VERSION ""

NS_ :

BS_:

BU_: ENGINE ABS AIRBAG TRANSMISSION BMS MOTOR HYBRID REGEN

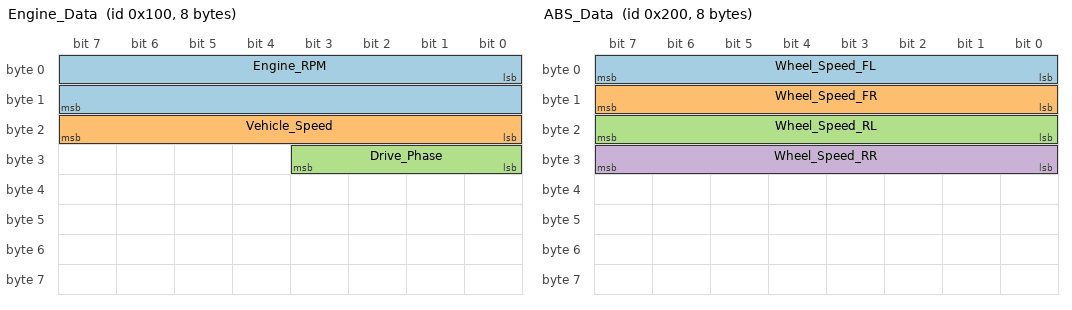
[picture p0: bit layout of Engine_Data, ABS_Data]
BO_ 256 Engine_Data: 8 ENGINE
 SG_ Engine_RPM : 0|16@1+ (1,0) [0|8000] "rpm" Vector__XXX
 SG_ Vehicle_Speed : 16|8@1+ (1,0) [0|250] "km/h" Vector__XXX
 SG_ Drive_Phase : 24|4@1+ (1,0) [0|15] "" Vector__XXX

BO_ 257 Engine_Status: 8 ENGINE
 SG_ Engine_Temp : 0|8@1+ (1,0) [-40|215] "C" Vector__XXX
 SG_ Throttle_Pos : 8|8@1+ (1,0) [0|100] "%" Vector__XXX

BO_ 512 ABS_Data: 8 ABS
 SG_ Wheel_Speed_FL : 0|8@1+ (1,0) [0|250] "km/h" Vector__XXX
 SG_ Wheel_Speed_FR : 8|8@1+ (1,0) [0|250] "km/h" Vector__XXX
 SG_ Wheel_Speed_RL : 16|8@1+ (1,0) [0|250] "km/h" Vector__XXX
 SG_ Wheel_Speed_RR : 24|8@1+ (1,0) [0|250] "km/h" Vector__XXX

BO_ 513 ABS_Status: 8 ABS
 SG_ Brake_Pressure : 0|8@1+ (1,0) [0|200] "bar" Vector__XXX

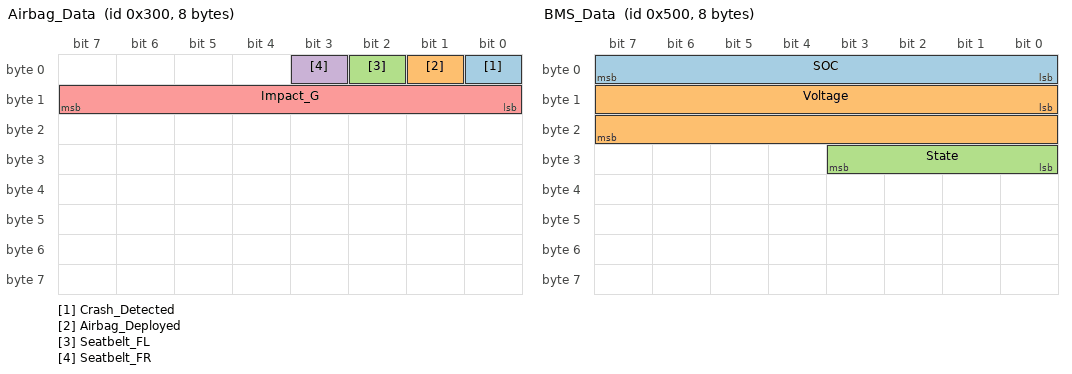
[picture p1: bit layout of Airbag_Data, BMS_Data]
BO_ 768 Airbag_Data: 8 AIRBAG
 SG_ Crash_Detected : 0|1@1+ (1,0) [0|1] "" Vector__XXX
 SG_ Airbag_Deployed : 1|1@1+ (1,0) [0|1] "" Vector__XXX
 SG_ Seatbelt_FL : 2|1@1+ (1,0) [0|1] "" Vector__XXX
 SG_ Seatbelt_FR : 3|1@1+ (1,0) [0|1] "" Vector__XXX
 SG_ Impact_G : 8|8@1+ (0.1,0) [0|25] "G" Vector__XXX

BO_ 1024 Transmission_Data: 8 TRANSMISSION
 SG_ Gear : 0|4@1+ (1,0) [0|15] "" Vector__XXX
 SG_ Drive_Mode : 4|4@1+ (1,0) [0|15] "" Vector__XXX

BO_ 1280 BMS_Data: 8 BMS
 SG_ SOC : 0|8@1+ (0.5,0) [0|100] "%" Vector__XXX
 SG_ Voltage : 8|16@1+ (0.1,0) [0|500] "V" Vector__XXX
 SG_ State : 24|4@1+ (1,0) [0|15] "" Vector__XXX

BO_ 1281 BMS_Status: 8 BMS
 SG_ Temp_Max : 0|8@1+ (1,-40) [-40|150] "C" Vector__XXX
 SG_ Temp_Min : 8|8@1+ (1,-40) [-40|150] "C" Vector__XXX

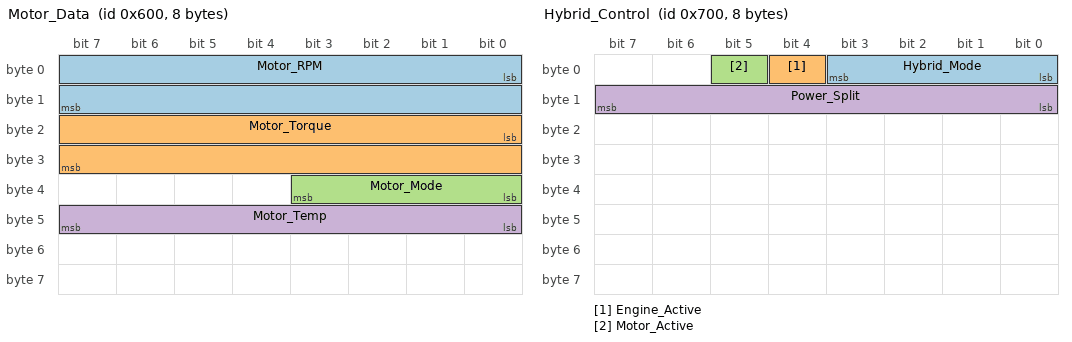
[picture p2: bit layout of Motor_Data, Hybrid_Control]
BO_ 1536 Motor_Data: 8 MOTOR
 SG_ Motor_RPM : 0|16@1- (1,0) [-10000|10000] "rpm" Vector__XXX
 SG_ Motor_Torque : 16|16@1- (0.1,0) [-500|500] "Nm" Vector__XXX
 SG_ Motor_Mode : 32|4@1+ (1,0) [0|15] "" Vector__XXX
 SG_ Motor_Temp : 40|8@1+ (1,-40) [-40|150] "C" Vector__XXX

BO_ 1792 Hybrid_Control: 8 HYBRID
 SG_ Hybrid_Mode : 0|4@1+ (1,0) [0|15] "" Vector__XXX
 SG_ Engine_Active : 4|1@1+ (1,0) [0|1] "" Vector__XXX
 SG_ Motor_Active : 5|1@1+ (1,0) [0|1] "" Vector__XXX
 SG_ Power_Split : 8|8@1+ (1,0) [0|100] "%" Vector__XXX

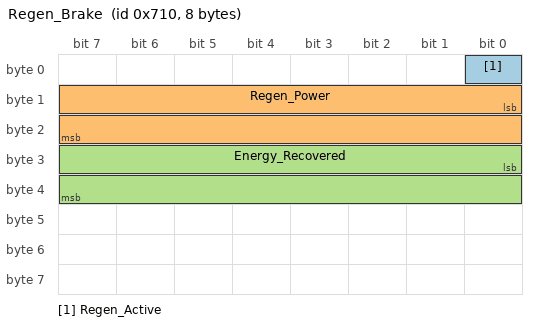
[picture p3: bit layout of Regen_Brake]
BO_ 1808 Regen_Brake: 8 REGEN
 SG_ Regen_Active : 0|1@1+ (1,0) [0|1] "" Vector__XXX
 SG_ Regen_Power : 8|16@1+ (0.1,0) [0|500] "kW" Vector__XXX
 SG_ Energy_Recovered : 24|16@1+ (0.1,0) [0|5000] "Wh" Vector__XXX

VAL_ 256 Drive_Phase 0 "IDLE" 1 "ACCELERATING" 2 "CITY" 3 "HIGHWAY_ACCEL" 4 "HIGHWAY" 5 "HIGHWAY_DECEL" 6 "DECELERATING" 7 "STOPPED" ;
VAL_ 1024 Drive_Mode 0 "P" 1 "R" 2 "N" 3 "D" ;
VAL_ 1792 Hybrid_Mode 0 "IDLE" 1 "EV" 2 "HV" 3 "BOOST" 4 "REGEN" ;
